AUTOSAR XML (schema 4-3-1)
package /Component
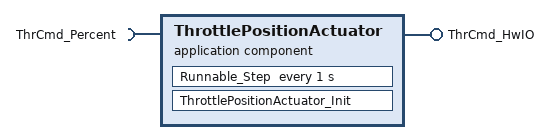
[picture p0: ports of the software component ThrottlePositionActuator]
  application sw component type ThrottlePositionActuator
    provide port ThrCmd_HwIO: nonqueued-sender-com-spec{data-element=Value_3, init-value=0}, provided-interface=ThrCmd_HwIO
    require port ThrCmd_Percent: nonqueued-receiver-com-spec{data-element=Value_4, init-value=0}, required-interface=ThrCmd_Percent
    behavior test_IB: handle-termination-and-restart=NO-SUPPORT
      timing event Event_Runnable_Step: start-on-event=Runnable_Step, period=1
      runnable Runnable_Step
        data-read-access:
          access IN_ThrCmd_Percent_Value_4: accessed-variable=ThrCmd_Percent.Value_4
        data-write-access:
          access OUT_ThrCmd_HwIO_Value_3: accessed-variable=ThrCmd_HwIO.Value_3
      runnable ThrottlePositionActuator_Init
      per-instance-parameters:
        parameter data prototype HBridgeCmd_LkupTbl: category=CURVE, sw-calibration-access=READ-WRITE, type=Appl_HBridgeCmd_LkupTbl, init-value=constant-reference={short-label=HBridgeCmd_LkupTbl, constant=HBridgeCmd_LkupTbl}
